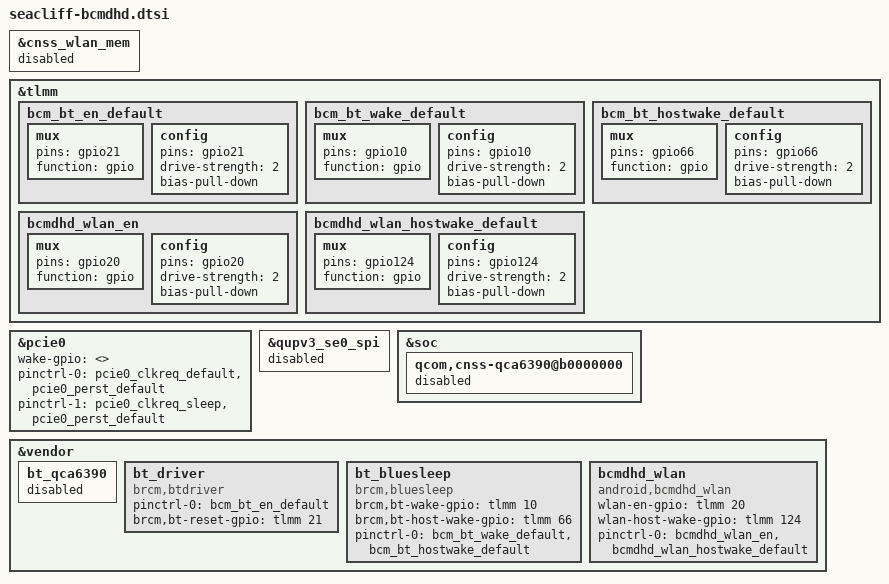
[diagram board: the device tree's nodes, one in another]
&cnss_wlan_mem {
	status = "disabled";
};

&tlmm {
	bcm_bt_en_default: bcm_bt_en_default {
		mux {
			pins = "gpio21";
			function = "gpio";
		};
		config {
			pins = "gpio21";
			drive-strength = <2>;
			/*output-low;*/
			bias-pull-down;
		};
	};

	bcm_bt_wake_default: bcm_bt_wake_default {
		mux {
			pins = "gpio10";
			function = "gpio";
		};
		config {
			pins = "gpio10";
			drive-strength = <2>;
			bias-pull-down;
		};
	};

	bcm_bt_hostwake_default: bcm_bt_hostwake_default {
		mux {
			pins = "gpio66";
			function = "gpio";
		};
		config {
			pins = "gpio66";
			drive-strength = <2>;
			bias-pull-down;
			};
	};

	bcmdhd_wlan_en: bcmdhd_wlan_en {
		mux {
			pins = "gpio20";
			function = "gpio";
			};
		config {
			pins = "gpio20";
			drive-strength = <2>;
			/*output-low;*/
			bias-pull-down;
		};
	};

	bcmdhd_wlan_hostwake_default: bcmdhd_wlan_hostwake_default {
		mux {
			pins = "gpio124";
			function = "gpio";
		};
		config {
			pins = "gpio124";
			drive-strength = <2>;
			/*output-low;*/
			bias-pull-down;
		};
	};
};

&pcie0 {
	wake-gpio = <>;
	pinctrl-0 = <&pcie0_clkreq_default &pcie0_perst_default>;
	pinctrl-1 = <&pcie0_clkreq_sleep &pcie0_perst_default>;
};

&qupv3_se0_spi {
	status = "disabled";
};

&soc {
	qcom,cnss-qca6390@b0000000 {
		status = "disabled";
	};
};

&vendor {
	/* disable qcom bt chip */
	bt_qca6390 {
		status = "disabled";
	};

	bt_driver {
		compatible = "brcm,btdriver";
		pinctrl-names = "default";
		pinctrl-0 = <&bcm_bt_en_default>;
		brcm,bt-reset-gpio = <&tlmm 21 0>;
		status = "ok";
	};

	bt_bluesleep: bt_bluesleep {
		compatible = "brcm,bluesleep";
		brcm,bt-wake-gpio = <&tlmm 10 0>;
		brcm,bt-host-wake-gpio = <&tlmm 66 0>;
		pinctrl-names = "default";
		pinctrl-0 = <&bcm_bt_wake_default &bcm_bt_hostwake_default>;
		status = "ok";
	};

	bcmdhd_wlan {
		compatible = "android,bcmdhd_wlan";
		wlan-en-gpio = <&tlmm 20 0>;
		wlan-host-wake-gpio = <&tlmm 124 0>;
		/*wlan-smmu-iova-address = <0xa0000000 0x10000000>;*/
		pinctrl-names = "default";
		pinctrl-0 = <&bcmdhd_wlan_en &bcmdhd_wlan_hostwake_default>;
		status = "ok";
	};
};
